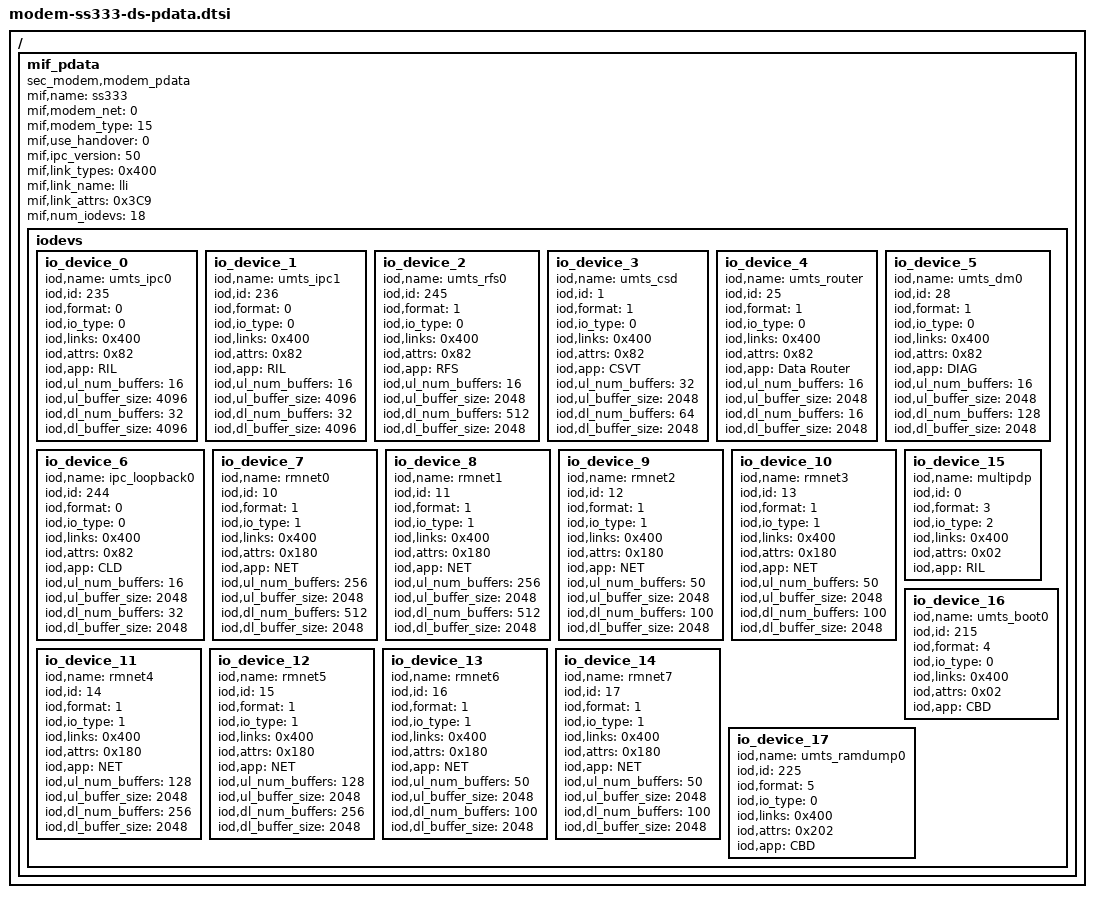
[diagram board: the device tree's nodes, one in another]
/*
 * SAMSUNG universal5422 board device tree source
 *
 * Copyright (c) 2013 Samsung Electronics Co., Ltd.
 *             http://www.samsung.com
 *
 * This program is free software; you can redistribute it and/or modify
 * it under the terms of the GNU General Public License version 2 as
 * published by the Free Software Foundation.
*/

/* modem_interface_driver: UMTS modem, 2G/3G/4G, Samsung Electronics Shannon333 (SS333) */

/ {
	mif_pdata {
		compatible = "sec_modem,modem_pdata";

		mif,name = "ss333";
		mif,modem_net = <0>;
		mif,modem_type = <15>;
		mif,use_handover = <0>;
		mif,ipc_version = <50>;
		mif,link_types = <0x400>;	/* LINKDEV_LLI */
		mif,link_name = "lli";
		mif,link_attrs = <0x3C9>;	/* DUMP_ALIGNED (0x200) | BOOT_ALIGNED (0x100) | MEM_DUMP (0x80) | MEM_BOOT (0x40) | DPRAM_MAGIC (0x08) | SBD_IPC (0x01) */

		mif,num_iodevs = <18>;
		iodevs {
			io_device_0 {
				iod,name = "umts_ipc0";
				iod,id = <235>;
				iod,format = <0>;
				iod,io_type = <0>;
				iod,links = <0x400>;
				iod,attrs = <0x82>;	/* ATTR_SBD_IPC | ATTR_SIPC5 */
				iod,app = "RIL";
				iod,ul_num_buffers = <16>;
				iod,ul_buffer_size = <4096>;
				iod,dl_num_buffers = <32>;
				iod,dl_buffer_size = <4096>;
			};
			io_device_1 {
				iod,name = "umts_ipc1";
				iod,id = <236>;
				iod,format = <0>;
				iod,io_type = <0>;
				iod,links = <0x400>;
				iod,attrs = <0x82>;	/* ATTR_SBD_IPC | ATTR_SIPC5 */
				iod,app = "RIL";
				iod,ul_num_buffers = <16>;
				iod,ul_buffer_size = <4096>;
				iod,dl_num_buffers = <32>;
				iod,dl_buffer_size = <4096>;
			};
			io_device_2 {
				iod,name = "umts_rfs0";
				iod,id = <245>;
				iod,format = <1>;
				iod,io_type = <0>;
				iod,links = <0x400>;
				iod,attrs = <0x82>;
				iod,app = "RFS";
				iod,ul_num_buffers = <16>;
				iod,ul_buffer_size = <2048>;
				iod,dl_num_buffers = <512>;
				iod,dl_buffer_size = <2048>;
			};
			io_device_3 {
				iod,name = "umts_csd";
				iod,id = <1>;
				iod,format = <1>;
				iod,io_type = <0>;
				iod,links = <0x400>;
				iod,attrs = <0x82>;
				iod,app = "CSVT";
				iod,ul_num_buffers = <32>;
				iod,ul_buffer_size = <2048>;
				iod,dl_num_buffers = <64>;
				iod,dl_buffer_size = <2048>;
			};
			io_device_4 {
				iod,name = "umts_router";
				iod,id = <25>;
				iod,format = <1>;
				iod,io_type = <0>;
				iod,links = <0x400>;
				iod,attrs = <0x82>;
				iod,app = "Data Router";
				iod,ul_num_buffers = <16>;
				iod,ul_buffer_size = <2048>;
				iod,dl_num_buffers = <16>;
				iod,dl_buffer_size = <2048>;
			};
			io_device_5 {
				iod,name = "umts_dm0";
				iod,id = <28>;
				iod,format = <1>;
				iod,io_type = <0>;
				iod,links = <0x400>;
				iod,attrs = <0x82>;
				iod,app = "DIAG";
				iod,ul_num_buffers = <16>;
				iod,ul_buffer_size = <2048>;
				iod,dl_num_buffers = <128>;
				iod,dl_buffer_size = <2048>;
			};
			io_device_6 {
				iod,name = "ipc_loopback0";
				iod,id = <244>;
				iod,format = <0>;
				iod,io_type = <0>;
				iod,links = <0x400>;
				iod,attrs = <0x82>;	/* ATTR_SBD_IPC | ATTR_SIPC5 */
				iod,app = "CLD";
				iod,ul_num_buffers = <16>;
				iod,ul_buffer_size = <2048>;
				iod,dl_num_buffers = <32>;
				iod,dl_buffer_size = <2048>;
			};
			io_device_7 {
				iod,name = "rmnet0";
				iod,id = <10>;
				iod,format = <1>;
				iod,io_type = <1>;
				iod,links = <0x400>;
				iod,attrs = <0x180>;
				iod,app = "NET";
				iod,ul_num_buffers = <256>;
				iod,ul_buffer_size = <2048>;
				iod,dl_num_buffers = <512>;
				iod,dl_buffer_size = <2048>;
			};
			io_device_8 {
				iod,name = "rmnet1";
				iod,id = <11>;
				iod,format = <1>;
				iod,io_type = <1>;
				iod,links = <0x400>;
				iod,attrs = <0x180>;
				iod,app = "NET";
				iod,ul_num_buffers = <256>;
				iod,ul_buffer_size = <2048>;
				iod,dl_num_buffers = <512>;
				iod,dl_buffer_size = <2048>;
			};
			io_device_9 {
				iod,name = "rmnet2";
				iod,id = <12>;
				iod,format = <1>;
				iod,io_type = <1>;
				iod,links = <0x400>;
				iod,attrs = <0x180>;
				iod,app = "NET";
				iod,ul_num_buffers = <50>;
				iod,ul_buffer_size = <2048>;
				iod,dl_num_buffers = <100>;
				iod,dl_buffer_size = <2048>;
			};
			io_device_10 {
				iod,name = "rmnet3";
				iod,id = <13>;
				iod,format = <1>;
				iod,io_type = <1>;
				iod,links = <0x400>;
				iod,attrs = <0x180>;
				iod,app = "NET";
				iod,ul_num_buffers = <50>;
				iod,ul_buffer_size = <2048>;
				iod,dl_num_buffers = <100>;
				iod,dl_buffer_size = <2048>;
			};
			io_device_11 {
				iod,name = "rmnet4";
				iod,id = <14>;
				iod,format = <1>;
				iod,io_type = <1>;
				iod,links = <0x400>;
				iod,attrs = <0x180>;
				iod,app = "NET";
				iod,ul_num_buffers = <128>;
				iod,ul_buffer_size = <2048>;
				iod,dl_num_buffers = <256>;
				iod,dl_buffer_size = <2048>;
			};
			io_device_12 {
				iod,name = "rmnet5";
				iod,id = <15>;
				iod,format = <1>;
				iod,io_type = <1>;
				iod,links = <0x400>;
				iod,attrs = <0x180>;
				iod,app = "NET";
				iod,ul_num_buffers = <128>;
				iod,ul_buffer_size = <2048>;
				iod,dl_num_buffers = <256>;
				iod,dl_buffer_size = <2048>;
			};
			io_device_13 {
				iod,name = "rmnet6";
				iod,id = <16>;
				iod,format = <1>;
				iod,io_type = <1>;
				iod,links = <0x400>;
				iod,attrs = <0x180>;
				iod,app = "NET";
				iod,ul_num_buffers = <50>;
				iod,ul_buffer_size = <2048>;
				iod,dl_num_buffers = <100>;
				iod,dl_buffer_size = <2048>;
			};
			io_device_14 {
				iod,name = "rmnet7";
				iod,id = <17>;
				iod,format = <1>;
				iod,io_type = <1>;
				iod,links = <0x400>;
				iod,attrs = <0x180>;
				iod,app = "NET";
				iod,ul_num_buffers = <50>;
				iod,ul_buffer_size = <2048>;
				iod,dl_num_buffers = <100>;
				iod,dl_buffer_size = <2048>;
			};
			io_device_15 {
				iod,name = "multipdp";
				iod,id = <0>;
				iod,format = <3>;
				iod,io_type = <2>;
				iod,links = <0x400>;
				iod,attrs = <0x02>;
				iod,app = "RIL";
			};
			io_device_16 {
				iod,name = "umts_boot0";
				iod,id = <215>;
				iod,format = <4>;
				iod,io_type = <0>;
				iod,links = <0x400>;
				iod,attrs = <0x02>;	/* ATTR_SIPC5 */
				iod,app = "CBD";
			};
			io_device_17 {
				iod,name = "umts_ramdump0";
				iod,id = <225>;
				iod,format = <5>;
				iod,io_type = <0>;
				iod,links = <0x400>;
				iod,attrs = <0x202>;	/* ATTR_NO_CHECK_MAXQ | ATTR_SIPC5 */
				iod,app = "CBD";
			};
		}; /* end of iodevs */
	}; /* end of mif_pdata */
};
